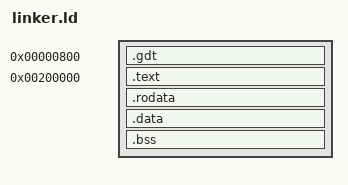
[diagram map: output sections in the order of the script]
ENTRY(_start)

_gdt_start = 0x00000800;

SECTIONS
{
	.gdt _gdt_start :
	{
		*(.gdt)
	}

	. = 2M;

	.text BLOCK(4K) : ALIGN(4K)
	{
		*(.multiboot)
		*(.text)
	}

	.rodata BLOCK(4K) : ALIGN(4K)
	{
		*(.rodata)
	}

	.data BLOCK(4K) : ALIGN(4K)
	{
		*(.data)
	}

	.bss BLOCK(4K) : ALIGN(4K)
	{
		*(COMMON)
		*(.bss)
	}
}
